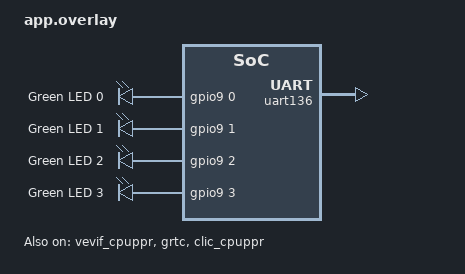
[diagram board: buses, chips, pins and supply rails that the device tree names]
/*
 * Copyright (c) 2022 Nordic Semiconductor ASA
 *
 * SPDX-License-Identifier: LicenseRef-Nordic-5-Clause
 */

/ {
	chosen {
		zephyr,console = &uart136;
	};

	allocatable_ram {
		#address-cells = <1>;
		#size-cells = <1>;

		/* Configure RAM region.
		 * This is done to ensure correct UICR generation.
		 */
		ram3x_app_ppr: memory@2fc00000 {
			compatible = "nordic,allocatable-ram";
			reg = <0x2fc00000 DT_SIZE_K(32)>;
			perm-read;
			perm-write;
		};
	};

	/* Redefine leds to fit CAF requirements. */
	/delete-node/ leds;

	leds012 {
		compatible = "gpio-leds";
		status = "okay";
		label = "ML State LED";

		led0: led_0 {
			gpios = < &gpio9 0 GPIO_ACTIVE_HIGH >;
			label = "Green LED 0";
		};

		led1: led_1 {
			gpios = < &gpio9 1 GPIO_ACTIVE_HIGH >;
			label = "Green LED 1";
		};

		led2: led_2 {
			gpios = < &gpio9 2 GPIO_ACTIVE_HIGH >;
			label = "Green LED 2";
		};
	};

	leds3 {
		compatible = "gpio-leds";
		led3: led_3 {
			gpios = < &gpio9 3 GPIO_ACTIVE_HIGH >;
			label = "Green LED 3";
		};
	};
};

/* Reserve peripheral for cpuppr in the default (multicore) configuration. */
&spi130 {
	status = "reserved";
	/* Configure IRQ to be forwarded to CPUPPR (13). */
	global-irqs = <421 421 13>;
};

ipc0: &ipc_to_cpuppr {
	status = "okay";
};

&vevif_cpuppr {
	status = "okay";
};

&ram3x_cpuapp {
	status = "okay";
};

&uart136 {
	status = "okay";
	memory-regions = <&ram3x_cpuapp>;
};

&uart135 {
	status = "reserved";
};

&gpio9 {
	status = "okay";
};

&grtc {
	status = "okay";
};

&clic_cpuppr {
	status = "okay";
};

&systick {
	status = "disabled";
};
